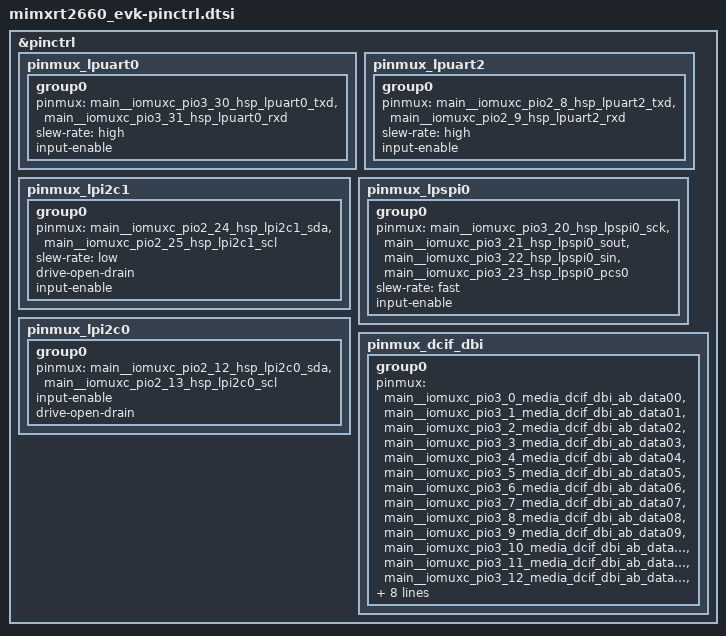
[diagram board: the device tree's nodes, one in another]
/*
 * SPDX-FileCopyrightText: Copyright 2026 NXP
 *
 * SPDX-License-Identifier: Apache-2.0
 */

/*
 * Board pinctrl for the MIMXRT2660-EVK.
 *
 * input-enable is required on any pad the peripheral reads back (IBENA bit).
 * drive-strength is only available on PIO5/PIO6/PIO7 pads; groups on
 * PIO0..PIO4 omit it.
 */

#include <nxp/imxrt/imxrt266x/pinctrl/mimxrt2663cvvaa-pinctrl.dtsi>

&pinctrl {
	/* Debug console: LPUART0 on PIO3_30 (TXD) / PIO3_31 (RXD). */
	pinmux_lpuart0: pinmux_lpuart0 {
		group0 {
			pinmux = <&main__iomuxc_pio3_30_hsp_lpuart0_txd>,
				 <&main__iomuxc_pio3_31_hsp_lpuart0_rxd>;
			slew-rate = "high";
			input-enable;
		};
	};

	/* Alternate UART: LPUART2 on PIO2_8 (TXD) / PIO2_9 (RXD). */
	pinmux_lpuart2: pinmux_lpuart2 {
		group0 {
			pinmux = <&main__iomuxc_pio2_8_hsp_lpuart2_txd>,
				 <&main__iomuxc_pio2_9_hsp_lpuart2_rxd>;
			slew-rate = "high";
			input-enable;
		};
	};

	/*
	 * LPI2C1 on PIO2_24 (SDA) / PIO2_25 (SCL) -- the bus the on-board
	 * P3T1755DP sensor (U28) sits on, which is why this instance rather than
	 * LPI2C0, whose pins only reach unpopulated headers. A 0-ohm jumper picks
	 * I2C1 over I3C on each ball (R349 SDA, R347 SCL), fitted on the I2C1 side.
	 *
	 * No internal pull-up: the board pulls both up (R273/R290, 4.7k). Without
	 * input-enable the master reads SCL as permanently low, takes it for clock
	 * stretching and issues no clocks at all -- the transfer then sits with
	 * MSR.MBF set and no event flags.
	 */
	pinmux_lpi2c1: pinmux_lpi2c1 {
		group0 {
			pinmux = <&main__iomuxc_pio2_24_hsp_lpi2c1_sda>,
				 <&main__iomuxc_pio2_25_hsp_lpi2c1_scl>;
			slew-rate = "low";
			drive-open-drain;
			input-enable;
		};
	};

	/*
	 * LPSPI0 on PIO3_20..23; needs J53 at 1-2 to route these pads to LPSPI0
	 * (default 2-3 routes them to the LCD interface).
	 */
	pinmux_lpspi0: pinmux_lpspi0 {
		group0 {
			pinmux = <&main__iomuxc_pio3_20_hsp_lpspi0_sck>,
				 <&main__iomuxc_pio3_21_hsp_lpspi0_sout>,
				 <&main__iomuxc_pio3_22_hsp_lpspi0_sin>,
				 <&main__iomuxc_pio3_23_hsp_lpspi0_pcs0>;
			slew-rate = "fast";
			input-enable;
		};
	};

	/* LPI2C0 on PIO2_12 (SDA) / PIO2_13 (SCL): PCAL6524 + PCA9555 expanders. */
	pinmux_lpi2c0: pinmux_lpi2c0 {
		group0 {
			pinmux = <&main__iomuxc_pio2_12_hsp_lpi2c0_sda>,
				 <&main__iomuxc_pio2_13_hsp_lpi2c0_scl>;
			input-enable;
			drive-open-drain;
		};
	};

	/* DCIF DBI (Type B/8080, 16-bit data + CSX + DCS + RDX + WRX) */
	pinmux_dcif_dbi: pinmux_dcif_dbi {
		group0 {
			pinmux = <&main__iomuxc_pio3_0_media_dcif_dbi_ab_data00>,
				 <&main__iomuxc_pio3_1_media_dcif_dbi_ab_data01>,
				 <&main__iomuxc_pio3_2_media_dcif_dbi_ab_data02>,
				 <&main__iomuxc_pio3_3_media_dcif_dbi_ab_data03>,
				 <&main__iomuxc_pio3_4_media_dcif_dbi_ab_data04>,
				 <&main__iomuxc_pio3_5_media_dcif_dbi_ab_data05>,
				 <&main__iomuxc_pio3_6_media_dcif_dbi_ab_data06>,
				 <&main__iomuxc_pio3_7_media_dcif_dbi_ab_data07>,
				 <&main__iomuxc_pio3_8_media_dcif_dbi_ab_data08>,
				 <&main__iomuxc_pio3_9_media_dcif_dbi_ab_data09>,
				 <&main__iomuxc_pio3_10_media_dcif_dbi_ab_data10>,
				 <&main__iomuxc_pio3_11_media_dcif_dbi_ab_data11>,
				 <&main__iomuxc_pio3_12_media_dcif_dbi_ab_data12>,
				 <&main__iomuxc_pio3_13_media_dcif_dbi_ab_data13>,
				 <&main__iomuxc_pio3_14_media_dcif_dbi_ab_data14>,
				 <&main__iomuxc_pio3_15_media_dcif_dbi_ab_data15>,
				 <&main__iomuxc_pio3_16_media_dcif_dbi_csx_ab>,
				 <&main__iomuxc_pio3_17_media_dcif_dbi_ab_dcs>,
				 <&main__iomuxc_pio3_18_media_dcif_dbi_b_rdx>,
				 <&main__iomuxc_pio3_19_media_dcif_dbi_a_rwx_or_b_wrx>;
			slew-rate = "high";
		};
	};
};
